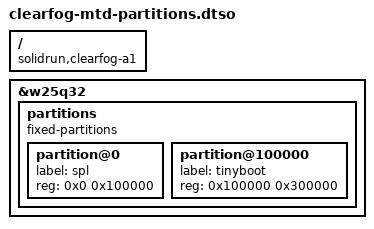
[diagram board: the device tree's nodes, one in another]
/dts-v1/;
/plugin/;

/ {
	compatible = "solidrun,clearfog-a1";
};

&w25q32 {
	partitions {
		compatible = "fixed-partitions";
		#address-cells = <1>;
		#size-cells = <1>;

		partition@0 {
			label = "spl";
			reg = <0x0 0x100000>;
		};

		/* CONFIG_SYS_SPI_KERNEL_OFFS, where SPL looks for the payload */
		partition@100000 {
			label = "tinyboot";
			reg = <0x100000 0x300000>;
		};
	};
};
